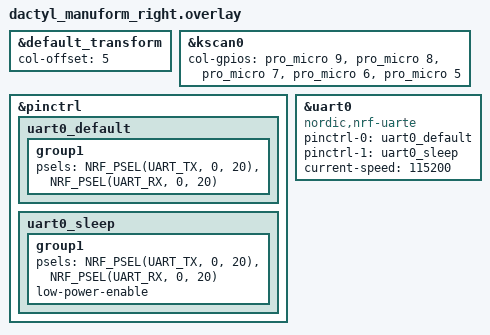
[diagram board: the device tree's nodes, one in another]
#include "dactyl_manuform.dtsi"

&default_transform {
    col-offset = <5>;
};

&kscan0 {
    col-gpios
        = <&pro_micro 9 GPIO_ACTIVE_HIGH>
        , <&pro_micro 8 GPIO_ACTIVE_HIGH>
        , <&pro_micro 7 GPIO_ACTIVE_HIGH>
        , <&pro_micro 6 GPIO_ACTIVE_HIGH>
        , <&pro_micro 5 GPIO_ACTIVE_HIGH>
        ;
};

&pinctrl {
    uart0_default: uart0_default {
        group1 {
            psels = <NRF_PSEL(UART_TX, 0, 20)>,
                    <NRF_PSEL(UART_RX, 0, 20)>;
        };
    };

    uart0_sleep: uart0_sleep {
        group1 {
            psels = <NRF_PSEL(UART_TX, 0, 20)>,
                    <NRF_PSEL(UART_RX, 0, 20)>;
            low-power-enable;
        };
    };
};

&uart0 {
    status = "okay";
    compatible = "nordic,nrf-uarte";
    pinctrl-0 = <&uart0_default>;
    pinctrl-1 = <&uart0_sleep>;
    pinctrl-names = "default", "sleep";
    current-speed = <115200>;
};
